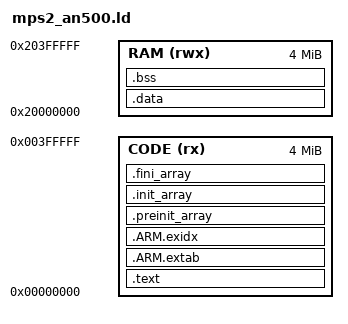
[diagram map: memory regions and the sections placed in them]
ENTRY(Reset_Handler)

MEMORY
{
    CODE (rx) : ORIGIN = 0x00000000, LENGTH = 4M
    RAM (rwx) : ORIGIN = 0x20000000, LENGTH = 4M
}

SECTIONS
{
    .text :
    {
        KEEP(*(.vectors))
        *(.text*)
        KEEP(*(.init))
        KEEP(*(.fini))
        *(.rodata*)
        . = ALIGN(4);
    } > CODE

    .ARM.extab : { *(.ARM.extab* .gnu.linkonce.armextab.*) } > CODE

    .ARM.exidx :
    {
        __exidx_start = .;
        *(.ARM.exidx* .gnu.linkonce.armexidx.*)
        __exidx_end = .;
    } > CODE

    .preinit_array :
    {
        PROVIDE_HIDDEN(__preinit_array_start = .);
        KEEP(*(.preinit_array*))
        PROVIDE_HIDDEN(__preinit_array_end = .);
    } > CODE

    .init_array :
    {
        PROVIDE_HIDDEN(__init_array_start = .);
        KEEP(*(SORT(.init_array.*)))
        KEEP(*(.init_array*))
        PROVIDE_HIDDEN(__init_array_end = .);
    } > CODE

    .fini_array :
    {
        PROVIDE_HIDDEN(__fini_array_start = .);
        KEEP(*(SORT(.fini_array.*)))
        KEEP(*(.fini_array*))
        PROVIDE_HIDDEN(__fini_array_end = .);
    } > CODE

    .data : { *(.data*) . = ALIGN(4); } > RAM

    .bss (NOLOAD) :
    {
        __bss_start__ = .;
        *(.bss*)
        *(COMMON)
        . = ALIGN(8);
        __bss_end__ = .;
    } > RAM

    end = .;
    PROVIDE(_end = .);
    PROVIDE(__end__ = .);
    __stack_top = ORIGIN(RAM) + LENGTH(RAM);
}
